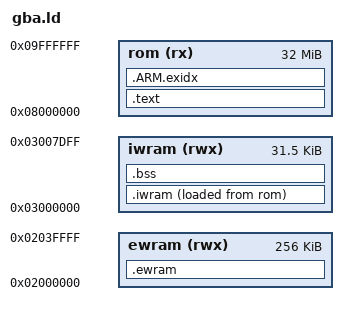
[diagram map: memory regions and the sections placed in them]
/* Linker script for The Devil's Revolver (cartridge ROM, IWRAM fast code) */
OUTPUT_FORMAT("elf32-littlearm")
OUTPUT_ARCH(arm)
ENTRY(_start)

MEMORY {
    rom   (rx)  : ORIGIN = 0x08000000, LENGTH = 32M
    iwram (rwx) : ORIGIN = 0x03000000, LENGTH = 0x7E00
    ewram (rwx) : ORIGIN = 0x02000000, LENGTH = 256K
}

SECTIONS {
    .text : {
        KEEP(*(.header))
        KEEP(*(.text.start))
        *(.text .text.*)
        *(.rodata .rodata.*)
        *(.glue_7) *(.glue_7t) *(.vfp11_veneer) *(.v4_bx)
        . = ALIGN(4);
    } > rom

    .ARM.exidx : { *(.ARM.exidx*) } > rom

    __iwram_lma = LOADADDR(.iwram);
    .iwram : ALIGN(4) {
        __iwram_start = .;
        *(.iwram .iwram.*)
        *(.data .data.*)
        . = ALIGN(4);
        __iwram_end = .;
    } > iwram AT > rom

    .bss (NOLOAD) : ALIGN(4) {
        __bss_start = .;
        *(.bss .bss.*) *(COMMON)
        . = ALIGN(4);
        __bss_end = .;
    } > iwram

    .ewram (NOLOAD) : ALIGN(4) {
        __ewram_bss_start = .;
        *(.ewram.bss .ewram.bss.*)
        . = ALIGN(4);
        __ewram_bss_end = .;
    } > ewram

    /DISCARD/ : { *(.ARM.attributes) *(.comment) *(.note*) }
}
